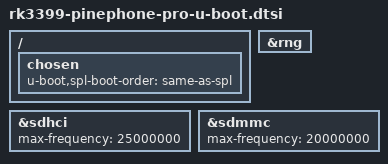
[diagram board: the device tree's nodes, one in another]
// SPDX-License-Identifier: GPL-2.0+
/*
 * Copyright (C) 2022 Peter Robinson <pbrobinson at gmail.com>
 */

#include "rk3399-u-boot.dtsi"
#include "rk3399-sdram-lpddr4-100.dtsi"

/ {
	chosen {
		u-boot,spl-boot-order = "same-as-spl", &sdhci, &sdmmc;
	};
};

&rng {
	status = "okay";
};

&sdhci {
	max-frequency = <25000000>;
	bootph-all;
};

&sdmmc {
	max-frequency = <20000000>;
	bootph-all;
};
